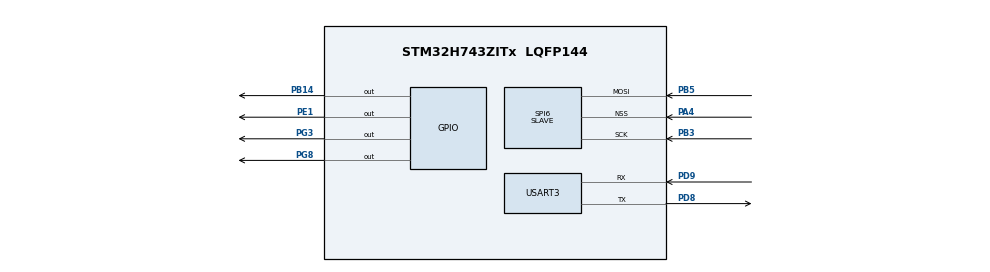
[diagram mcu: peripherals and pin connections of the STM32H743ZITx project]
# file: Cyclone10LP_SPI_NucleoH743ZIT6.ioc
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CORTEX_M7.default_mode_Activation=1
Mcu.Family=STM32H7
Mcu.Name=STM32H743ZITx
Mcu.Package=LQFP144
NVIC.PriorityGroup=NVIC_PRIORITYGROUP_4
NVIC.SPI6_IRQn=true\:0\:0\:false\:false\:true\:true\:true\:true
PA4.Mode=NSS_Signal_Hard_Input
PA4.Signal=SPI6_NSS
PB14.Signal=GPIO_Output
PB3\ (JTDO/TRACESWO).Mode=RX_Only_Simplex_Unidirect_Slave
PB3\ (JTDO/TRACESWO).Signal=SPI6_SCK
PB4\ (NJTRST).Signal=SPI6_MISO
PB5.Mode=RX_Only_Simplex_Unidirect_Slave
PB5.Signal=SPI6_MOSI
PC14-OSC32_IN\ (OSC32_IN).Mode=LSE-External-Oscillator
PC14-OSC32_IN\ (OSC32_IN).Signal=RCC_OSC32_IN
PC15-OSC32_OUT\ (OSC32_OUT).Mode=LSE-External-Oscillator
PC15-OSC32_OUT\ (OSC32_OUT).Signal=RCC_OSC32_OUT
PD8.Mode=Asynchronous
PD8.Signal=USART3_TX
PD9.Mode=Asynchronous
PD9.Signal=USART3_RX
PE1.Signal=GPIO_Output
PG3.Signal=GPIO_Output
PG8.Signal=GPIO_Output
PH0-OSC_IN\ (PH0).Mode=HSE-External-Oscillator
PH0-OSC_IN\ (PH0).Signal=RCC_OSC_IN
PH1-OSC_OUT\ (PH1).Mode=HSE-External-Oscillator
PH1-OSC_OUT\ (PH1).Signal=RCC_OSC_OUT
ProjectManager.HeapSize=0x200
ProjectManager.StackSize=0x400
ProjectManager.TargetToolchain=STM32CubeIDE
RCC.ADCFreq_Value=129000000
RCC.APB1Freq_Value=64000000
RCC.APB2Freq_Value=64000000
RCC.APB3Freq_Value=64000000
RCC.APB4Freq_Value=64000000
RCC.CortexFreq_Value=64000000
RCC.DIVQ2=6
RCC.HCLKFreq_Value=64000000
RCC.SPI6CLockSelection=RCC_SPI6CLKSOURCE_PLL2
RCC.SYSCLKFreq_VALUE=64000000
RCC.USART234578CLockSelection=RCC_USART234578CLKSOURCE_PLL2
RCC.USBFreq_Value=129000000
SPI6.CLKPhase=SPI_PHASE_2EDGE
SPI6.CLKPolarity=SPI_POLARITY_LOW
SPI6.DataSize=SPI_DATASIZE_8BIT
SPI6.Direction=SPI_DIRECTION_2LINES_RXONLY
SPI6.Mode=SPI_MODE_SLAVE
SPI6.VirtualNSS=VM_NSSHARD
SPI6.VirtualType=VM_SLAVE
USART3.VirtualMode-Asynchronous=VM_ASYNC
VP_MEMORYMAP_VS_MEMORYMAP.Mode=CurAppReg
board=custom

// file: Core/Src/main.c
/* USER CODE BEGIN Header */
/**
  ******************************************************************************
  * @file           : main.c
  * @brief          : Main program body
  ******************************************************************************
  * @attention
  *
  * Copyright (c) 2024 STMicroelectronics.
  * All rights reserved.
  *
  * This software is licensed under terms that can be found in the LICENSE file
  * in the root directory of this software component.
  * If no LICENSE file comes with this software, it is provided AS-IS.
  *
  ******************************************************************************
  */
/* USER CODE END Header */
#include "main.h"
#include "memorymap.h"
#include "spi.h"
#include "usart.h"
#include "gpio.h"

/* USER CODE BEGIN PV */
uint8_t rx_data[10] =  {1,2,3,4,5,6,7,8};						// Define Global Variable as UART Buffer
uint8_t tx_data[10] =  {0xff,0x82,0xff,0x04};					// Define Global Variable as UART Buffer
/* USER CODE END PV */

void SystemClock_Config(void);
void PeriphCommonClock_Config(void);
static void MPU_Config(void);

int main(void)
{

  /* MPU Configuration--------------------------------------------------------*/
  MPU_Config();

  /* MCU Configuration--------------------------------------------------------*/

  /* Reset of all peripherals, Initializes the Flash interface and the Systick. */
  HAL_Init();

  /* Configure the system clock */
  SystemClock_Config();

  /* Configure the peripherals common clocks */
  PeriphCommonClock_Config();

  /* Initialize all configured peripherals */
  MX_GPIO_Init();
  MX_SPI6_Init();
  MX_USART3_UART_Init();
  /* USER CODE BEGIN 2 */
  HAL_SPI_Receive_IT(&hspi6, rx_data, 4U);
  /* USER CODE END 2 */

  /* Infinite loop */
  while (1)
  {

    /* USER CODE BEGIN 3 */
	  //HAL_GPIO_WritePin(GPIOG, GPIO_PIN_3, GPIO_PIN_RESET);							// Pulls the SPI line down low
	  //HAL_SPI_Receive_IT(&hspi6, rx_data, 4U);											// Single SPI Receive in Regular Mode
	  //HAL_GPIO_WritePin(GPIOG, GPIO_PIN_3, GPIO_PIN_SET);								// Pulls the SPI line back high
	  HAL_GPIO_TogglePin(GPIOB, GPIO_PIN_14); 											// Toggle LED to show the system is running
	  HAL_Delay(1000);
	  /*
	  HAL_GPIO_WritePin(GPIOG, GPIO_PIN_3, GPIO_PIN_RESET);
	  HAL_SPI_Transmit(&hspi6, rx_data, 8U, 1000);
	  HAL_GPIO_TogglePin(GPIOB, GPIO_PIN_14);
	  HAL_GPIO_WritePin(GPIOG, GPIO_PIN_3, GPIO_PIN_SET);
	  HAL_Delay(1000); */

	  // FPGA Signal Tap - no need for delays
	  //HAL_GPIO_WritePin(GPIOG, GPIO_PIN_3, GPIO_PIN_RESET);				// Toggle LED to show the system is running
	  //HAL_GPIO_WritePin(GPIOG, GPIO_PIN_3, GPIO_PIN_SET);

  }
  /* USER CODE END 3 */
}

void SystemClock_Config(void)
{
  RCC_OscInitTypeDef RCC_OscInitStruct = {0};
  RCC_ClkInitTypeDef RCC_ClkInitStruct = {0};

  /** Supply configuration update enable
  */
  HAL_PWREx_ConfigSupply(PWR_LDO_SUPPLY);

  /** Configure the main internal regulator output voltage
  */
  __HAL_PWR_VOLTAGESCALING_CONFIG(PWR_REGULATOR_VOLTAGE_SCALE3);

  while(!__HAL_PWR_GET_FLAG(PWR_FLAG_VOSRDY)) {}

  /** Macro to configure the PLL clock source
  */
  __HAL_RCC_PLL_PLLSOURCE_CONFIG(RCC_PLLSOURCE_HSI);

  /** Initializes the RCC Oscillators according to the specified parameters
  * in the RCC_OscInitTypeDef structure.
  */
  RCC_OscInitStruct.OscillatorType = RCC_OSCILLATORTYPE_HSI;
  RCC_OscInitStruct.HSIState = RCC_HSI_DIV1;
  RCC_OscInitStruct.HSICalibrationValue = RCC_HSICALIBRATION_DEFAULT;
  RCC_OscInitStruct.PLL.PLLState = RCC_PLL_NONE;
  if (HAL_RCC_OscConfig(&RCC_OscInitStruct) != HAL_OK)
  {
    Error_Handler();
  }

  /** Initializes the CPU, AHB and APB buses clocks
  */
  RCC_ClkInitStruct.ClockType = RCC_CLOCKTYPE_HCLK|RCC_CLOCKTYPE_SYSCLK
                              |RCC_CLOCKTYPE_PCLK1|RCC_CLOCKTYPE_PCLK2
                              |RCC_CLOCKTYPE_D3PCLK1|RCC_CLOCKTYPE_D1PCLK1;
  RCC_ClkInitStruct.SYSCLKSource = RCC_SYSCLKSOURCE_HSI;
  RCC_ClkInitStruct.SYSCLKDivider = RCC_SYSCLK_DIV1;
  RCC_ClkInitStruct.AHBCLKDivider = RCC_HCLK_DIV1;
  RCC_ClkInitStruct.APB3CLKDivider = RCC_APB3_DIV1;
  RCC_ClkInitStruct.APB1CLKDivider = RCC_APB1_DIV1;
  RCC_ClkInitStruct.APB2CLKDivider = RCC_APB2_DIV1;
  RCC_ClkInitStruct.APB4CLKDivider = RCC_APB4_DIV1;

  if (HAL_RCC_ClockConfig(&RCC_ClkInitStruct, FLASH_LATENCY_1) != HAL_OK)
  {
    Error_Handler();
  }
}

void PeriphCommonClock_Config(void)
{
  RCC_PeriphCLKInitTypeDef PeriphClkInitStruct = {0};

  /** Initializes the peripherals clock
  */
  PeriphClkInitStruct.PeriphClockSelection = RCC_PERIPHCLK_SPI6|RCC_PERIPHCLK_USART3;
  PeriphClkInitStruct.PLL2.PLL2M = 32;
  PeriphClkInitStruct.PLL2.PLL2N = 129;
  PeriphClkInitStruct.PLL2.PLL2P = 2;
  PeriphClkInitStruct.PLL2.PLL2Q = 6;
  PeriphClkInitStruct.PLL2.PLL2R = 2;
  PeriphClkInitStruct.PLL2.PLL2RGE = RCC_PLL2VCIRANGE_1;
  PeriphClkInitStruct.PLL2.PLL2VCOSEL = RCC_PLL2VCOWIDE;
  PeriphClkInitStruct.PLL2.PLL2FRACN = 0;
  PeriphClkInitStruct.Usart234578ClockSelection = RCC_USART234578CLKSOURCE_PLL2;
  PeriphClkInitStruct.Spi6ClockSelection = RCC_SPI6CLKSOURCE_PLL2;
  if (HAL_RCCEx_PeriphCLKConfig(&PeriphClkInitStruct) != HAL_OK)
  {
    Error_Handler();
  }
}

/* USER CODE BEGIN 4 */
// SPI Receive Complete Callback
// This function is called everytime the SPI Receive is completed.
void HAL_SPI_TxCpltCallback(SPI_HandleTypeDef *hspi) {
    if (hspi->Instance == SPI6) {
        // Data reception complete, print in serial terminal
    	HAL_GPIO_TogglePin(GPIOE, GPIO_PIN_1);
    	//HAL_UART_Transmit(&huart3, (uint8_t *)rx_data, sizeof(4U), 100);

    	// Single SPI Receive gets the SPI ready for any incoming traffic via SPI
    	/*
    	 if (HAL_SPI_Receive_IT(&hspi6, (uint8_t*)rx_data, sizeof(4U)) != HAL_OK) {
    	  		// Reception Error
    	  		Error_Handler();
    	 }*/
    }
}

void HAL_SPI_RxCpltCallback(SPI_HandleTypeDef *hspi) {
    if (hspi->Instance == SPI6) {
        // Data reception complete, print in serial terminal
    	//HAL_GPIO_TogglePin(GPIOE, GPIO_PIN_1);
    	HAL_UART_Transmit(&huart3, (uint8_t *)rx_data, sizeof(4U), 100);
    	HAL_SPI_Transmit(&hspi6, (uint8_t*)tx_data, sizeof(4U), 10000);
    	HAL_SPI_Receive_IT(&hspi6, (uint8_t*)rx_data, sizeof(4U));
    	// Single SPI Receive gets the SPI ready for any incoming traffic via SPI
    	/*
    	 if (HAL_SPI_Receive_IT(&hspi6, (uint8_t*)rx_data, sizeof(4U)) != HAL_OK) {
    	  		// Reception Error
    	  		Error_Handler();
    	 }*/
    }
}
/* USER CODE END 4 */

 /* MPU Configuration */

void MPU_Config(void)
{
  MPU_Region_InitTypeDef MPU_InitStruct = {0};

  /* Disables the MPU */
  HAL_MPU_Disable();

  /** Initializes and configures the Region and the memory to be protected
  */
  MPU_InitStruct.Enable = MPU_REGION_ENABLE;
  MPU_InitStruct.Number = MPU_REGION_NUMBER0;
  MPU_InitStruct.BaseAddress = 0x0;
  MPU_InitStruct.Size = MPU_REGION_SIZE_4GB;
  MPU_InitStruct.SubRegionDisable = 0x87;
  MPU_InitStruct.TypeExtField = MPU_TEX_LEVEL0;
  MPU_InitStruct.AccessPermission = MPU_REGION_NO_ACCESS;
  MPU_InitStruct.DisableExec = MPU_INSTRUCTION_ACCESS_DISABLE;
  MPU_InitStruct.IsShareable = MPU_ACCESS_SHAREABLE;
  MPU_InitStruct.IsCacheable = MPU_ACCESS_NOT_CACHEABLE;
  MPU_InitStruct.IsBufferable = MPU_ACCESS_NOT_BUFFERABLE;

  HAL_MPU_ConfigRegion(&MPU_InitStruct);
  /* Enables the MPU */
  HAL_MPU_Enable(MPU_PRIVILEGED_DEFAULT);

}

void Error_Handler(void)
{
  __disable_irq();
  while (1)
  {
  }
}
